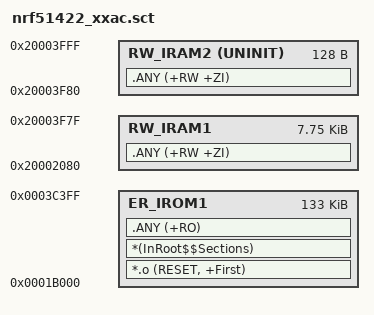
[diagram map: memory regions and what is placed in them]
; *************************************************************
; *** Scatter-Loading Description File generated by uVision ***
; *************************************************************

LR_IROM1 0x0001B000 0x00021400  {    ; load region size_region
  ER_IROM1 0x0001B000 0x00021400  {  ; load address = execution address
   *.o (RESET, +First)
   *(InRoot$$Sections)
   .ANY (+RO)
  }
  RW_IRAM1 0x20002080 0x00001F00  {  ; RW data
   .ANY (+RW +ZI)
  }
  RW_IRAM2 0x20003F80 UNINIT 0x00000080  {
   .ANY (+RW +ZI)
  }
}

